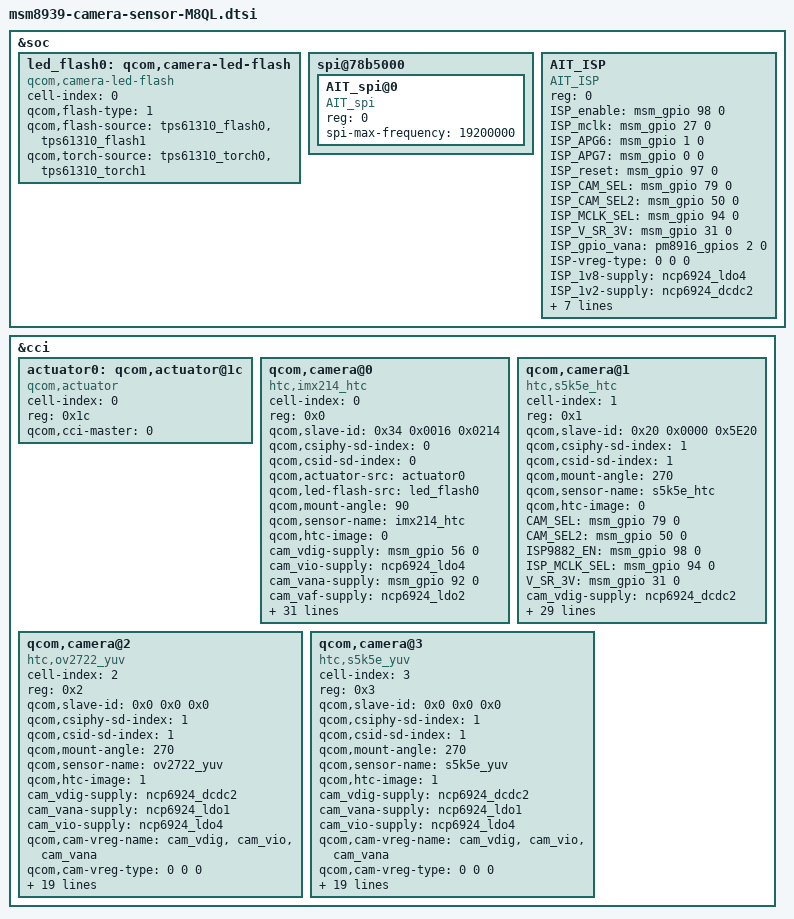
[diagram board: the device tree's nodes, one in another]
/*
 * Copyright (c) 2014, The Linux Foundation. All rights reserved.
 *
 * This program is free software; you can redistribute it and/or modify
 * it under the terms of the GNU General Public License version 2 and
 * only version 2 as published by the Free Software Foundation.
 *
 * This program is distributed in the hope that it will be useful,
 * but WITHOUT ANY WARRANTY; without even the implied warranty of
 * MERCHANTABILITY or FITNESS FOR A PARTICULAR PURPOSE.  See the
 * GNU General Public License for more details.
 */

&soc {

	led_flash0: qcom,camera-led-flash {
		cell-index = <0>;
		compatible = "qcom,camera-led-flash";
		qcom,flash-type = <1>;
		qcom,flash-source = <&tps61310_flash0 &tps61310_flash1>;
		qcom,torch-source = <&tps61310_torch0 &tps61310_torch1>;
	};
	spi@78b5000 {
		AIT_spi@0 {
			compatible = "AIT_spi";
			reg = <0>;
			spi-max-frequency = <19200000>;
		};

	};

	AIT_ISP {
		compatible = "AIT_ISP";
		reg = <0>;
		ISP_enable = <&msm_gpio 98 0>;
		ISP_mclk = <&msm_gpio 27 0>;
		ISP_APG6 = <&msm_gpio 1 0>;
		ISP_APG7 = <&msm_gpio 0 0>;
		ISP_reset = <&msm_gpio 97 0>;
		ISP_CAM_SEL = <&msm_gpio 79 0>;
		ISP_CAM_SEL2 = <&msm_gpio 50 0>;
		ISP_MCLK_SEL = <&msm_gpio 94 0>;
		ISP_V_SR_3V = <&msm_gpio 31 0>;
		ISP_gpio_vana = <&pm8916_gpios 2 0>;
		ISP-vreg-type = <0 0 0>;                //VREG type for below two item, 0 => VREG_TYPE_DEFAULT,  2=>VREG_TYPE_GPIO
		ISP_1v8-supply = <&ncp6924_ldo4>;
		ISP_1v2-supply = <&ncp6924_dcdc2>;
		ISP_A2v8-supply = <&ncp6924_ldo1>;
		pinctrl-names = "AIT_default", "AIT_suspend";
		pinctrl-0 = <&cam_sensor_mclk1_default &cam_sensor_front_default>;
		pinctrl-1 = <&cam_sensor_mclk1_sleep &cam_sensor_front_sleep>;
		interrupt-parent = <&msm_gpio>;
		interrupts = <102 0x4>;
		interrupt-names = "AIT_intr";
	};

};

&cci {

	actuator0: qcom,actuator@1c {
		cell-index = <0>;
		reg = <0x1c>;
		compatible = "qcom,actuator";
		qcom,cci-master = <0>;
	};

	qcom,camera@0 {
		cell-index = <0>;
		compatible = "htc,imx214_htc";
		reg = <0x0>;
		qcom,slave-id = <0x34 0x0016 0x0214>;
		qcom,csiphy-sd-index = <0>;
		qcom,csid-sd-index = <0>;
		qcom,actuator-src = <&actuator0>;
		qcom,led-flash-src = <&led_flash0>;
		qcom,mount-angle = <90>;
		qcom,sensor-name = "imx214_htc";
		qcom,htc-image = <0>;
		cam_vdig-supply = <&msm_gpio 56 0>;
		cam_vio-supply = <&ncp6924_ldo4>;
		cam_vana-supply = <&msm_gpio 92 0>;
		cam_vaf-supply = <&ncp6924_ldo2>;
		cam_vcustom1-supply = <&ncp6924_dcdc2>;//V_ISP_1V2
		qcom,cam-vreg-name = "cam_vdig", "cam_vio", "cam_vana", "cam_vaf", "cam_vcustom1";
		qcom,cam-vreg-type = <2 0 2 0 0>;
		qcom,cam-vreg-min-voltage = <0 1800000 0 2800000 1200000>;
		qcom,cam-vreg-max-voltage = <0 1800000 0 2800000 1200000>;
		qcom,cam-vreg-op-mode = <0 0 0 0 0>;
		qcom,cam-vreg-gpios-index = <99 99 99 99 99>;
		qcom,gpio-no-mux = <0>;
		pinctrl-names = "cam_default", "cam_suspend";
		pinctrl-0 = <&cam_sensor_mclk0_default
				&cam_sensor_rear_default>;
		pinctrl-1 = <&cam_sensor_mclk0_sleep &cam_sensor_rear_sleep>;
		gpios = <&msm_gpio 26 0>,
				<&msm_gpio 35 0>,
				<&msm_gpio 56 0>,
				<&msm_gpio 92 0>;
		qcom,gpio-reset = <1>;
		//qcom,gpio-vcm-pwd = <2>;
		qcom,gpio-vdig = <2>;
		qcom,gpio-vana = <3>;
		qcom,gpio-req-tbl-num = <0 1 2 3>;
		qcom,gpio-req-tbl-flags = <1 0 0 0>;
		qcom,gpio-req-tbl-label = "MCLK_CPU",
					              "CAM_RST",
					              "V_CAM_DVDD",
								  "V_CAM_A2V85";

		qcom,csi-lane-assign = <0x4320>;
		qcom,csi-lane-mask = <0x1F>;
		qcom,sensor-position = <0>;
		qcom,sensor-mode = <0>;
		qcom,cci-master = <0>;
		status = "ok";
		clocks = <&clock_gcc clk_mclk0_clk_src>,
				<&clock_gcc clk_gcc_camss_mclk0_clk>;
		clock-names = "cam_src_clk", "cam_clk";
	};

	qcom,camera@1 {
		cell-index = <1>;
		compatible = "htc,s5k5e_htc";
		reg = <0x1>;
		qcom,slave-id = <0x20 0x0000 0x5E20>;
		qcom,csiphy-sd-index = <1>;
		qcom,csid-sd-index = <1>;
		qcom,mount-angle = <270>;
		qcom,sensor-name = "s5k5e_htc";
		qcom,htc-image = <0>;
		CAM_SEL = <&msm_gpio 79 0>;
		CAM_SEL2 = <&msm_gpio 50 0>;
		ISP9882_EN = <&msm_gpio 98 0>;
		ISP_MCLK_SEL = <&msm_gpio 94 0>;
		V_SR_3V = <&msm_gpio 31 0>;
		cam_vdig-supply = <&ncp6924_dcdc2>;//V_ISP_1V2
		cam_vio-supply = <&ncp6924_ldo4>;
		cam_vana-supply = <&ncp6924_ldo1>;//V_ISP_A2V8
		qcom,cam-vreg-name = "cam_vdig", "cam_vio", "cam_vana";
		qcom,cam-vreg-type = <0 0 0>;
		qcom,cam-vreg-min-voltage = <1200000 1800000 2800000>;
		qcom,cam-vreg-max-voltage = <1200000 1800000 2800000>;
		qcom,cam-vreg-op-mode = <0 0 0>;
		qcom,cam-vreg-gpios-index = <99 99 99>;
		qcom,gpio-no-mux = <0>;
		pinctrl-names = "cam_default", "cam_suspend";
		pinctrl-0 = <&cam_sensor_mclk1_default>;
		pinctrl-1 = <&cam_sensor_mclk1_sleep>;
		gpios = <&msm_gpio 27 0>,
				<&msm_gpio 28 0>,
				<&pm8916_gpios 2 0>;
		qcom,gpio-reset = <1>;
		qcom,gpio-vana = <2>;
		qcom,gpio-req-tbl-num = <0 1 2>;
		qcom,gpio-req-tbl-flags = <1 0 0>;
		qcom,gpio-req-tbl-label = "MCLK_CPU",
						"CAM_RST",
						"V_CAM2_A2V85";

		qcom,csi-lane-assign = <0x4320>;
		qcom,csi-lane-mask = <0x7>;
		qcom,sensor-position = <1>;
		qcom,sensor-mode = <1>;
		qcom,cci-master = <0>;
		status = "ok";
		clocks = <&clock_gcc clk_mclk1_clk_src>,
				<&clock_gcc clk_gcc_camss_mclk1_clk>;
		clock-names = "cam_src_clk", "cam_clk";
	};

	qcom,camera@2 {
		cell-index = <2>;
		compatible = "htc,ov2722_yuv";
		reg = <0x2>;
		qcom,slave-id = <0x0 0x0 0x0>;
		qcom,csiphy-sd-index = <1>;
		qcom,csid-sd-index = <1>;
		qcom,mount-angle = <270>;
		qcom,sensor-name = "ov2722_yuv";
		qcom,htc-image = <1>;
		cam_vdig-supply = <&ncp6924_dcdc2>;
		cam_vana-supply = <&ncp6924_ldo1>;
		cam_vio-supply = <&ncp6924_ldo4>;
		qcom,cam-vreg-name = "cam_vdig", "cam_vio", "cam_vana";
		qcom,cam-vreg-type = <0 0 0>;
		qcom,cam-vreg-min-voltage = <1200000 1800000 2800000>;
		qcom,cam-vreg-max-voltage = <1200000 1800000 2800000>;
		qcom,cam-vreg-op-mode = <0 0 0>;
		qcom,cam-vreg-gpios-index = <99 99 99>;
		qcom,gpio-no-mux = <0>;
		//pinctrl-names = "cam_default", "cam_suspend";
		//pinctrl-0 = <&cam_sensor_front_default>;
		//pinctrl-1 = <&cam_sensor_front_sleep>;
		gpios = <&msm_gpio 95 0>;
		qcom,gpio-vana = <0>;
		qcom,gpio-req-tbl-num = <0>;
		qcom,gpio-req-tbl-flags = <0>;
		qcom,gpio-req-tbl-label = "V_CAM2_A2V85";

		qcom,csi-lane-assign = <0x4320>;
		qcom,csi-lane-mask = <0x3>;
		qcom,sensor-position = <2>;
		qcom,sensor-mode = <1>;
		qcom,cci-master = <0>;
		status = "ok";
		clocks = <&clock_gcc clk_mclk1_clk_src>,
				<&clock_gcc clk_gcc_camss_mclk1_clk>;
		clock-names = "cam_src_clk", "cam_clk";
	};

	qcom,camera@3 {
		cell-index = <3>;
		compatible = "htc,s5k5e_yuv";
		reg = <0x3>;
		qcom,slave-id = <0x0 0x0 0x0>;
		qcom,csiphy-sd-index = <1>;
		qcom,csid-sd-index = <1>;
		qcom,mount-angle = <270>;
		qcom,sensor-name = "s5k5e_yuv";
		qcom,htc-image = <1>;
		cam_vdig-supply = <&ncp6924_dcdc2>;
		cam_vana-supply = <&ncp6924_ldo1>;
		cam_vio-supply = <&ncp6924_ldo4>;
		qcom,cam-vreg-name = "cam_vdig", "cam_vio", "cam_vana";
		qcom,cam-vreg-type = <0 0 0>;
		qcom,cam-vreg-min-voltage = <1200000 1800000 2800000>;
		qcom,cam-vreg-max-voltage = <1200000 1800000 2800000>;
		qcom,cam-vreg-op-mode = <0 0 0>;
		qcom,cam-vreg-gpios-index = <99 99 99>;
		qcom,gpio-no-mux = <0>;
		//pinctrl-names = "cam_default", "cam_suspend";
		//pinctrl-0 = <&cam_sensor_front_default>;
		//pinctrl-1 = <&cam_sensor_front_sleep>;
		gpios = <&msm_gpio 95 0>;
		qcom,gpio-vana = <0>;
		qcom,gpio-req-tbl-num = <0>;
		qcom,gpio-req-tbl-flags = <0>;
		qcom,gpio-req-tbl-label = "V_CAM2_A2V85";

		qcom,csi-lane-assign = <0x4320>;
		qcom,csi-lane-mask = <0x7>;
		qcom,sensor-position = <3>;
		qcom,sensor-mode = <1>;
		qcom,cci-master = <0>;
		status = "ok";
		clocks = <&clock_gcc clk_mclk1_clk_src>,
				<&clock_gcc clk_gcc_camss_mclk1_clk>;
		clock-names = "cam_src_clk", "cam_clk";
	};


};
